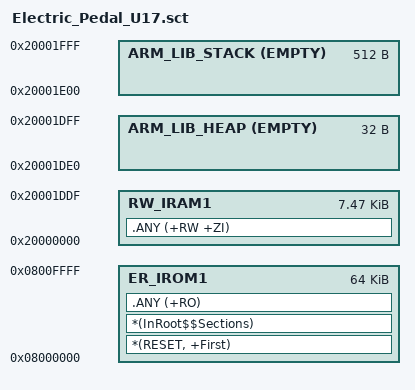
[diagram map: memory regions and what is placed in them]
LR_IROM1 0x08000000 0x00010000  {
  ER_IROM1 0x08000000 0x00010000  {
    *(RESET, +First)
    *(InRoot$$Sections)
    .ANY (+RO)
  }
  RW_IRAM1 0x20000000 0x00001DE0  {
    .ANY (+RW +ZI)
  }
  ARM_LIB_HEAP 0x20001DE0 EMPTY 0x00000020  { }
  ARM_LIB_STACK 0x20002000 EMPTY -0x00000200 { }
}
